AUTOSAR XML (schema 00048)
# ISO 26262 E-Gas three-level torque safety monitor. Hand-authored (not
# tool-generated) against the AUTOSAR 4.x schema to demonstrate the SWC
# interface, runnable, and timing. Original work, MIT licence. No proprietary
# content.
standard types defined: float32, uint8, boolean
package /DataTypes/ImplTypes
  4 x impl type, all with category=VALUE:
    Torque_T: base-type=float32
    Percent_T: base-type=float32
    Uint8_T: base-type=uint8
    Boolean_T: base-type=boolean
package /PortInterfaces
  4 x sender receiver interface:
    IF_Pedal
      data pct: type=Percent_T
    IF_Torque
      data nm: type=Torque_T
    IF_U8
      data val: type=Uint8_T
    IF_Bool
      data flag: type=Boolean_T
package /SwComponentTypes
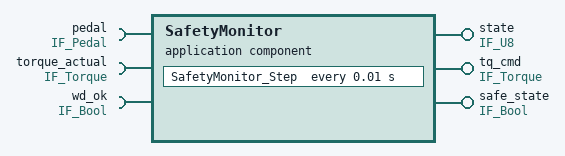
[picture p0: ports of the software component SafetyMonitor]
  application sw component type SafetyMonitor
    require port pedal: required-interface=IF_Pedal
    require port torque_actual: required-interface=IF_Torque
    require port wd_ok: required-interface=IF_Bool
    provide port state: provided-interface=IF_U8
    provide port tq_cmd: provided-interface=IF_Torque
    provide port safe_state: provided-interface=IF_Bool
    behavior SafetyMonitor_IB
      timing event EV_10ms: start-on-event=SafetyMonitor_Step, period=0.01
      runnable SafetyMonitor_Step
